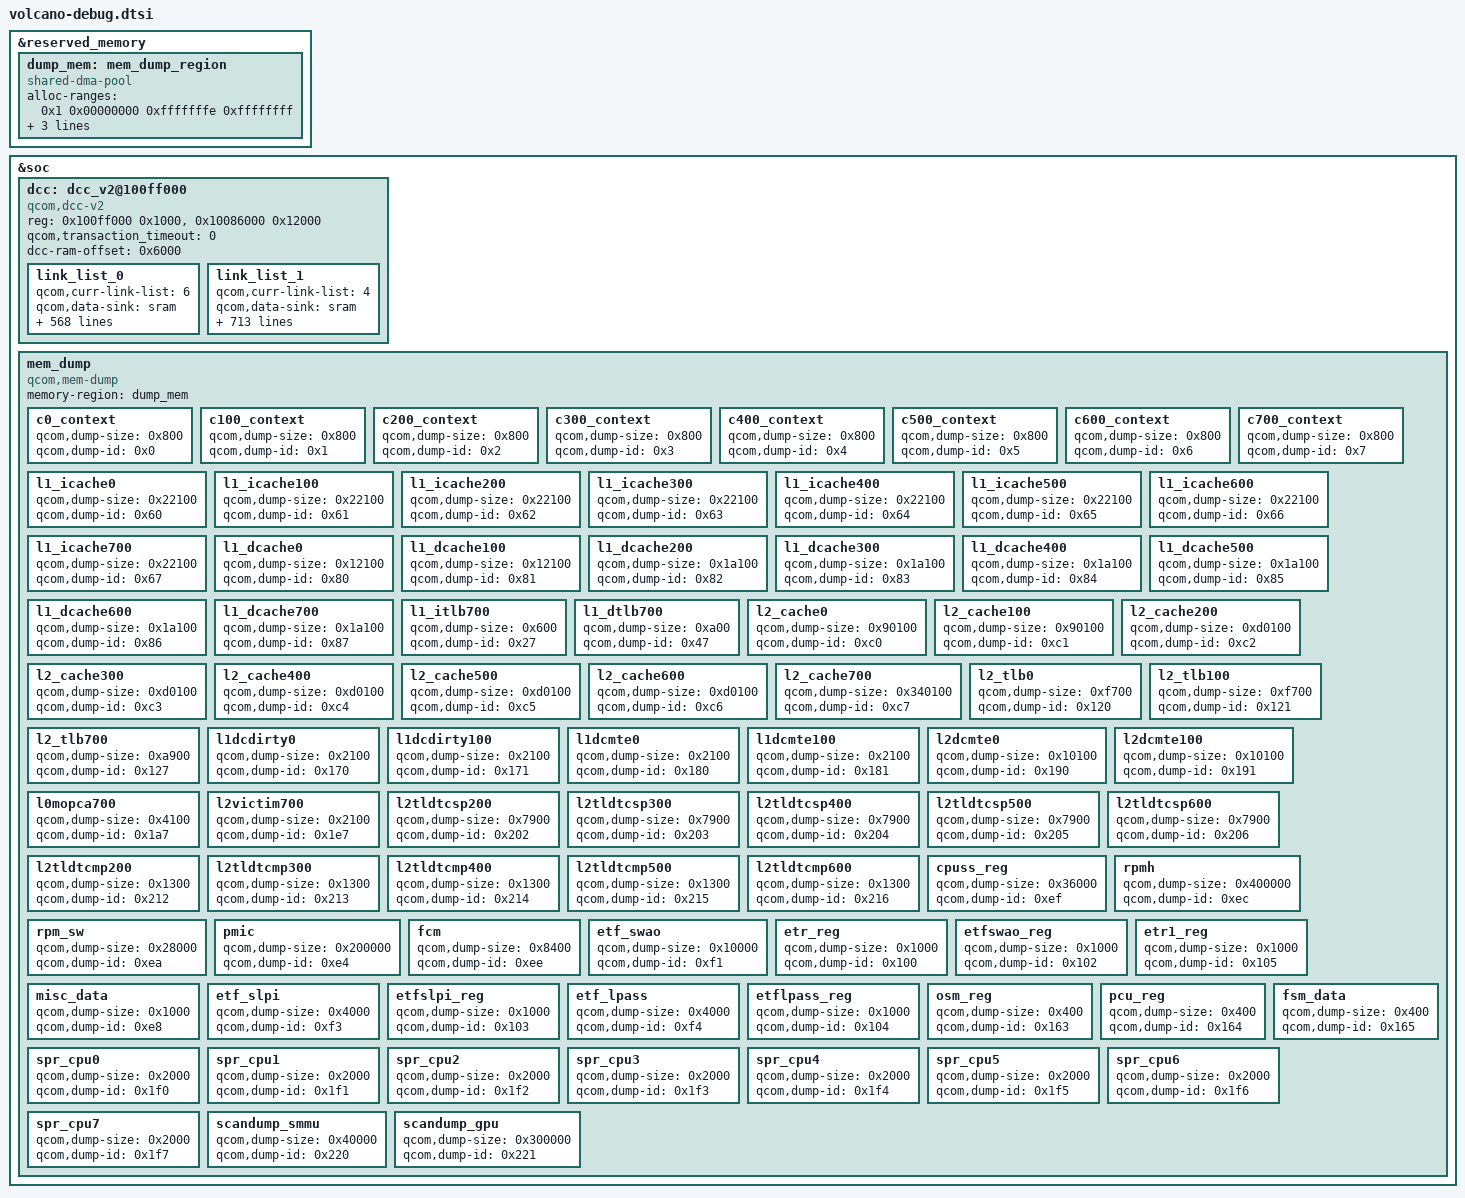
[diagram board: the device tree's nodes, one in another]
#include <dt-bindings/soc/qcom,dcc_v2.h>

&reserved_memory {
	#address-cells = <2>;
	#size-cells = <2>;
	ranges;

	dump_mem: mem_dump_region {
		compatible = "shared-dma-pool";
		alloc-ranges = <0x1 0x00000000 0xfffffffe 0xffffffff>;
		reusable;
		alignment = <0x0 0x400000>;
		size = <0 0x1800000>;
	};
};

&soc {
	dcc: dcc_v2@100ff000 {
		compatible = "qcom,dcc-v2";
		reg = <0x100ff000 0x1000>,
		      <0x10086000 0x12000>;

		qcom,transaction_timeout = <0>;

		reg-names = "dcc-base", "dcc-ram-base";
		dcc-ram-offset = <0x6000>;

		link_list_0 {
			qcom,curr-link-list = <6>;
			qcom,data-sink = "sram";
			qcom,ap-qad-override;
			qcom,link-list = <DCC_READ 0x17421000 2 0>,
				<DCC_READ 0x1780005c 1 0>,
				<DCC_READ 0x1781005c 1 0>,
				<DCC_READ 0x1782005c 1 0>,
				<DCC_READ 0x1783005c 1 0>,
				<DCC_READ 0x1784005c 1 0>,
				<DCC_READ 0x1785005c 1 0>,
				<DCC_READ 0x1786005c 1 0>,
				<DCC_READ 0x1787005c 1 0>,
				<DCC_READ 0x1740003c 1 0>,
				<DCC_READ 0x17600238 1 0>,
				<DCC_READ 0x17600240 11 0>,
				<DCC_READ 0x17600274 1 0>,
				<DCC_READ 0x17600530 1 0>,
				<DCC_READ 0x1760051c 1 0>,
				<DCC_READ 0x17600524 1 0>,
				<DCC_READ 0x1760052c 1 0>,
				<DCC_READ 0x17600518 1 0>,
				<DCC_READ 0x17600520 1 0>,
				<DCC_READ 0x17600528 1 0>,
				<DCC_READ 0x17600404 4 0>,
				<DCC_READ 0x1760041c 4 0>,
				<DCC_READ 0x17600434 1 0>,
				<DCC_READ 0x1760043c 1 0>,
				<DCC_READ 0x17600440 1 0>,
				<DCC_READ 0x17400438 1 0>,
				<DCC_READ 0x17600044 1 0>,
				<DCC_READ 0x17600500 1 0>,
				<DCC_READ 0x221c209c 1 0>,
				<DCC_READ 0x17600504 4 0>,
				<DCC_READ 0x17900908 1 0>,
				<DCC_READ 0x17900c18 1 0>,
				<DCC_READ 0x17901908 1 0>,
				<DCC_READ 0x17901c18 1 0>,
				<DCC_READ 0x17b90810 3 0>,
				<DCC_READ 0x17b90c50 3 0>,
				<DCC_READ 0x17b93a04 2 0>,
				<DCC_READ 0x17b93c94 1 0>,
				<DCC_READ 0x17ba0810 3 0>,
				<DCC_READ 0x17ba0c50 3 0>,
				<DCC_READ 0x17ba3a04 2 0>,
				<DCC_READ 0x17ba3c94 1 0>,
				<DCC_READ 0x17b93000 80 0>,
				<DCC_READ 0x17ba3000 80 0>,
				<DCC_READ 0x0c201244 1 0>,
				<DCC_READ 0x0c202244 1 0>,
				<DCC_READ 0x17b00000 1 0>,
				<DCC_READ 0x17a94030 1 0>,
				<DCC_READ 0x17a9408c 1 0>,
				<DCC_WRITE 0x17a9409c 0x78 0>,
				<DCC_WRITE 0x17a9409c 0x0  0>,
				<DCC_WRITE 0x17a94048 0x1  0>,
				<DCC_WRITE 0x17a94090 0x0  0>,
				<DCC_WRITE 0x17a94090 0x25 0>,
				<DCC_READ 0x17a94098 1 0>,
				<DCC_WRITE 0x17a94048 0x1d 0>,
				<DCC_WRITE 0x17a94090 0x0  0>,
				<DCC_WRITE 0x17a94090 0x25 0>,
				<DCC_READ 0x17a94098 1 0>,
				<DCC_READ 0x17a90030 1 0>,
				<DCC_READ 0x17a9008c 1 0>,
				<DCC_WRITE 0x17a9009c 0x78 0>,
				<DCC_WRITE 0x17a9009c 0x0  0>,
				<DCC_WRITE 0x17a90048 0x1  0>,
				<DCC_WRITE 0x17a90090 0x0  0>,
				<DCC_WRITE 0x17a90090 0x25 0>,
				<DCC_READ 0x17a90098 1 0>,
				<DCC_WRITE 0x17a90048 0x1d 0>,
				<DCC_WRITE 0x17a90090 0x0  0>,
				<DCC_WRITE 0x17a90090 0x25 0>,
				<DCC_READ 0x17a90098 1 0>,
				<DCC_READ 0x17a92030 1 0>,
				<DCC_READ 0x17a9208c 1 0>,
				<DCC_WRITE 0x17a9209c 0x78 0>,
				<DCC_WRITE 0x17a9209c 0x0  0>,
				<DCC_WRITE 0x17a92048 0x1  0>,
				<DCC_WRITE 0x17a92090 0x0  0>,
				<DCC_WRITE 0x17a92090 0x25 0>,
				<DCC_READ 0x17a92098 1 0>,
				<DCC_WRITE 0x17a92048 0x1d 0>,
				<DCC_WRITE 0x17a92090 0x0  0>,
				<DCC_WRITE 0x17a92090 0x25 0>,
				<DCC_READ 0x17a92098 1 0>,
				<DCC_READ 0x17a96030 1 0>,
				<DCC_READ 0x17a9608c 1 0>,
				<DCC_WRITE 0x17a9609c 0x78 0>,
				<DCC_WRITE 0x17a9609c 0x0  0>,
				<DCC_WRITE 0x17a96048 0x1  0>,
				<DCC_WRITE 0x17a96090 0x0  0>,
				<DCC_WRITE 0x17a96090 0x25 0>,
				<DCC_READ 0x17a96098 1 0>,
				<DCC_WRITE 0x17a96048 0x1d 0>,
				<DCC_WRITE 0x17a96090 0x0  0>,
				<DCC_WRITE 0x17a96090 0x25 0>,
				<DCC_READ 0x17a96098 1 0>,
				<DCC_READ 0x17d98024 1 0>,
				<DCC_READ 0x13822000 1 1>,
				<DCC_READ 0x221c20a4 1 0>,
				<DCC_READ 0x01fc8000 1 0>,
				<DCC_READ 0x17400038 1 0>,
				<DCC_READ 0x17d91020 1 0>,
				<DCC_READ 0x17d92020 1 0>,
				<DCC_READ 0x17d93020 1 0>,
				<DCC_READ 0x17d90020 1 0>,
				<DCC_READ 0x17d9134c 1 0>,
				<DCC_READ 0x17d9234c 1 0>,
				<DCC_READ 0x17d9334c 1 0>,
				<DCC_READ 0x17d9034c 1 0>,
				<DCC_READ 0x17d91300 1 0>,
				<DCC_READ 0x17d92300 1 0>,
				<DCC_READ 0x17d93300 1 0>,
				<DCC_READ 0x17d90300 1 0>,
				<DCC_READ 0x24104010 1 >,
				<DCC_READ 0x24104020 6 0>,
				<DCC_READ 0x24144010 1 0>,
				<DCC_READ 0x24144020 6 0>,
				<DCC_READ 0x24190010 1 0>,
				<DCC_READ 0x24190020 6 0>,
				<DCC_READ 0x24190410 1 0>,
				<DCC_READ 0x24190420 6 0>,
				<DCC_READ 0x24191048 1 0>,
				<DCC_READ 0x24100808 2 0>,
				<DCC_READ 0x24140808 2 0>,
				<DCC_READ 0x24101000 3 0>,
				<DCC_LOOP 0x3 0 0>,
				<DCC_READ 0x24101010 2 0>,
				<DCC_LOOP 0x1 0 0>,
				<DCC_READ 0x24101018 1 0>,
				<DCC_READ 0x24101080 1 0>,
				<DCC_READ 0x24101084 2 0>,
				<DCC_LOOP 0x5 0 0>,
				<DCC_READ 0x24101090 2 0>,
				<DCC_LOOP 0x1 0 0>,
				<DCC_READ 0x24101098 1 0>,
				<DCC_READ 0x24141000 1 0>,
				<DCC_READ 0x24141004 2 0>,
				<DCC_READ 0x24141010 2 0>,
				<DCC_READ 0x24141010 2 0>,
				<DCC_READ 0x24141018 1 0>,
				<DCC_READ 0x24141080 1 0>,
				<DCC_READ 0x24141084 1 0>,
				<DCC_LOOP 0x5 0 0>,
				<DCC_READ 0x24141090 2 0>,
				<DCC_LOOP 0x1 0 0>,
				<DCC_READ 0x24141098 1 0>,
				<DCC_READ 0x24181000 1 0>,
				<DCC_READ 0x24181004 2 0>,
				<DCC_LOOP 0x3 0 0>,
				<DCC_READ 0x24181010 2 0>,
				<DCC_LOOP 0x1 0 0>,
				<DCC_READ 0x24181018 1 0>,
				<DCC_READ 0x24181100 3 0>,
				<DCC_LOOP 0xc 0 0>,
				<DCC_READ 0x24181110 2 0>,
				<DCC_LOOP 0x1 0 0>,
				<DCC_READ 0x24181118 1 0>,
				<DCC_READ 0x24131010 1 >,
				<DCC_READ 0x24133010 1 >,
				<DCC_READ 0x24135010 1 >,
				<DCC_READ 0x24137010 1 >,
				<DCC_READ 0x24138010 1 >,
				<DCC_READ 0x24171010 1 >,
				<DCC_READ 0x24173010 1 >,
				<DCC_READ 0x24175010 1 >,
				<DCC_READ 0x24177010 1 >,
				<DCC_READ 0x24178010 1 >,
				<DCC_READ 0x241e2010 1 >,
				<DCC_READ 0x241e5010 1 >,
				<DCC_READ 0x241f1010 1 >,
				<DCC_READ 0x241f3010 1 >,
				<DCC_READ 0x241f5010 1 >,
				<DCC_READ 0x241f7010 1 >,
				<DCC_READ 0x241f9010 1 >,
				<DCC_READ 0x241fb010 1 >,
				<DCC_READ 0x241fc010 1 >,
				<DCC_READ 0x241fd010 1 >,
				<DCC_READ 0x241ff010 1 >,
				<DCC_READ 0x24100810 1 0>,
				<DCC_LOOP 0x40 0 0>,
				<DCC_READ 0x24100830 2 0>,
				<DCC_READ 0x24100830 2 0>,
				<DCC_READ 0x24100830 2 0>,
				<DCC_READ 0x24100830 2 0>,
				<DCC_LOOP 0x1 0 0>,
				<DCC_READ 0x24100838 1 0>,
				<DCC_READ 0x24140810 1 0>,
				<DCC_LOOP 0x40 0 0>,
				<DCC_READ 0x24140830 2 0>,
				<DCC_READ 0x24140830 2 0>,
				<DCC_READ 0x24140830 2 0>,
				<DCC_READ 0x24140830 2 0>,
				<DCC_LOOP 0x1 0 0>,
				<DCC_READ 0x24140838 1 0>,
				<DCC_READ 0x24180010 1 0>,
				<DCC_LOOP 0x10 0 0>,
				<DCC_READ 0x24180030 2 0>,
				<DCC_READ 0x24180030 2 0>,
				<DCC_READ 0x24180030 2 0>,
				<DCC_READ 0x24180030 2 0>,
				<DCC_LOOP 0x1 0 0>,
				<DCC_READ 0x24180038 1 0>,
				<DCC_READ 0x24180410 1 0>,
				<DCC_LOOP 0x10 0 0>,
				<DCC_READ 0x24180430 2 0>,
				<DCC_READ 0x24180430 2 0>,
				<DCC_READ 0x24180430 2 0>,
				<DCC_READ 0x24180430 2 0>,
				<DCC_LOOP 0x1 0 0>,
				<DCC_READ 0x24180438 1 0>,
				<DCC_READ 0x17800024  1 >,
				<DCC_READ 0x17800038  6>,
				<DCC_READ 0x17800058  4>,
				<DCC_READ 0x1780006c  1 >,
				<DCC_READ 0x178000f0  2>,
				<DCC_READ 0x17810024  1 >,
				<DCC_READ 0x17810038  6>,
				<DCC_READ 0x17810058  4>,
				<DCC_READ 0x1781006c  1 >,
				<DCC_READ 0x178100f0  2>,
				<DCC_READ 0x17820010  1 >,
				<DCC_READ 0x17820024  1 >,
				<DCC_READ 0x17820038  6>,
				<DCC_READ 0x17820058  4>,
				<DCC_READ 0x178200f0  2>,
				<DCC_READ 0x17830010  1 >,
				<DCC_READ 0x17830024  1 >,
				<DCC_READ 0x17830038  6>,
				<DCC_READ 0x17830058  4>,
				<DCC_READ 0x178300f0  2>,
				<DCC_READ 0x17840010  1 >,
				<DCC_READ 0x17840024  1 >,
				<DCC_READ 0x17840038  6>,
				<DCC_READ 0x17840058  4>,
				<DCC_READ 0x178400f0  2>,
				<DCC_READ 0x17850010  1 >,
				<DCC_READ 0x17850024  1 >,
				<DCC_READ 0x17850038  6>,
				<DCC_READ 0x17850058  4>,
				<DCC_READ 0x178500f0  2>,
				<DCC_READ 0x17860010  1 >,
				<DCC_READ 0x17860024  1 >,
				<DCC_READ 0x17860038  6>,
				<DCC_READ 0x17860058  4>,
				<DCC_READ 0x178600f0  2>,
				<DCC_READ 0x17870010  1 >,
				<DCC_READ 0x17870024  1 >,
				<DCC_READ 0x17870038  6>,
				<DCC_READ 0x17870058  4>,
				<DCC_READ 0x178700f0  2>,
				<DCC_READ 0x17880010  1 >,
				<DCC_READ 0x17880024  1 >,
				<DCC_READ 0x17880038  6>,
				<DCC_READ 0x17890010  1 >,
				<DCC_READ 0x17890024  1 >,
				<DCC_READ 0x17890038  6>,
				<DCC_READ 0x178b0010  1 >,
				<DCC_READ 0x178b0024  1 >,
				<DCC_READ 0x178b0038  6>,
				<DCC_READ 0x178b006c  5>,
				<DCC_READ 0x178b0084  1 >,
				<DCC_READ 0x178b00f4  5>,
				<DCC_READ 0x178b0118  9>,
				<DCC_READ 0x178b0158  5>,
				<DCC_READ 0x178b0170  2>,
				<DCC_READ 0x178b0188  5>,
				<DCC_READ 0x178b01ac  6>,
				<DCC_READ 0x178b01c8 1 >,
				<DCC_READ 0x178b0204 1 >,
				<DCC_READ 0x178b0244 1 >,
				<DCC_READ 0x17e30000 1 >,
				<DCC_READ 0x17e30008 1 >,
				<DCC_READ 0x17e30010 1 >,
				<DCC_READ 0x17e80000 1 >,
				<DCC_READ 0x17e80008 1 >,
				<DCC_READ 0x17e80010 1 >,
				<DCC_READ 0x17f80000 1 >,
				<DCC_READ 0x17f80008 1 >,
				<DCC_READ 0x17f80010 1 >,
				<DCC_READ 0x18080000 1 >,
				<DCC_READ 0x18080008 1 >,
				<DCC_READ 0x18080010 1 >,
				<DCC_READ 0x18180000 1 >,
				<DCC_READ 0x18180008 1 >,
				<DCC_READ 0x18180010 1 >,
				<DCC_READ 0x18280000 1 >,
				<DCC_READ 0x18280008 1 >,
				<DCC_READ 0x18280010 1 >,
				<DCC_READ 0x18380000 1 >,
				<DCC_READ 0x18380008 1 >,
				<DCC_READ 0x18380010 1 >,
				<DCC_READ 0x18480000 1 >,
				<DCC_READ 0x18480008 1 >,
				<DCC_READ 0x18480010 1 >,
				<DCC_READ 0x18580000 1 >,
				<DCC_READ 0x18580008 1 >,
				<DCC_READ 0x18580010 1 >,
				<DCC_READ 0x24453400 2 >,
				<DCC_READ 0x24042010 1 >,
				<DCC_READ 0x24042040 1 >,
				<DCC_READ 0x2404205c 1 >,
				<DCC_READ 0x24055008 1 >,
				<DCC_READ 0x24055070 1 >,
				<DCC_READ 0x24055948 1 >,
				<DCC_READ 0x24057008 1 >,
				<DCC_READ 0x24057018 1 >,
				<DCC_READ 0x24057028 1 >,
				<DCC_READ 0x24057038 1 >,
				<DCC_READ 0x24080024 1 >,
				<DCC_READ 0x2408002c 1 >,
				<DCC_READ 0x24080034 1 >,
				<DCC_READ 0x2408003c 1 >,
				<DCC_READ 0x24080044 1 >,
				<DCC_READ 0x2408004c 1 >,
				<DCC_READ 0x24080058 1 >,
				<DCC_READ 0x240800c8 1 >,
				<DCC_READ 0x24080144 1 >,
				<DCC_READ 0x2408014c 1 >,
				<DCC_READ 0x24080174 1 >,
				<DCC_READ 0x2408017c 1 >,
				<DCC_READ 0x24080184 1 >,
				<DCC_READ 0x2408018c 1 >,
				<DCC_READ 0x24080194 1 >,
				<DCC_READ 0x2408019c 1 >,
				<DCC_READ 0x240801a4 1 >,
				<DCC_READ 0x240801ac 1 >,
				<DCC_READ 0x24091000 1 >,
				<DCC_READ 0x24092000 1 >,
				<DCC_READ 0x24093000 1 >,
				<DCC_READ 0x24093104 1 >,
				<DCC_READ 0x24094000 1 >,
				<DCC_READ 0x24094000 1 >,
				<DCC_READ 0x24094104 1 >,
				<DCC_READ 0x24094104 1 >,
				<DCC_READ 0x24095220 9 0>,
				<DCC_READ 0x240a1008 1 >,
				<DCC_READ 0x240a80e4 1 >,
				<DCC_READ 0x240a80f8 1 >,
				<DCC_READ 0x240a8100 1 >,
				<DCC_READ 0x240a8110 1 >,
				<DCC_READ 0x240a8120 1 >,
				<DCC_READ 0x240a81c8 1 >,
				<DCC_READ 0x240a8234 1 >,
				<DCC_READ 0x240a82d4 1 >,
				<DCC_READ 0x240a8834 1 >,
				<DCC_READ 0x240a8840 1 >,
				<DCC_READ 0x240a8854 1 >,
				<DCC_READ 0x240a8860 1 >,
				<DCC_READ 0x240a8878 1 >,
				<DCC_READ 0x240a888c 1 >,
				<DCC_READ 0x240a9140 1 >,
				<DCC_READ 0x240a9140 1 >,
				<DCC_READ 0x240a9188 1 >,
				<DCC_READ 0x240a91b8 1 >,
				<DCC_READ 0x240aa034 1 >,
				<DCC_READ 0x240aa04c 1 >,
				<DCC_READ 0x240aa058 1 >,
				<DCC_READ 0x240aa064 1 >,
				<DCC_READ 0x240aa0d4 1 >,
				<DCC_READ 0x24401814 1 >,
				<DCC_READ 0x24403814 1 >,
				<DCC_READ 0x24405014 1 >,
				<DCC_READ 0x24405530 1 >,
				<DCC_READ 0x24406c04 1 >,
				<DCC_READ 0x24406d04 1 >,
				<DCC_READ 0x2440729c 1 >,
				<DCC_READ 0x244072a8 1 >,
				<DCC_READ 0x2440759c 1 >,
				<DCC_READ 0x244075a8 1 >,
				<DCC_READ 0x24443400 1 >,
				<DCC_READ 0x24443420 1 >,
				<DCC_READ 0x24443430 1 >,
				<DCC_READ 0x24443430 1 >,
				<DCC_READ 0x24443460 2 0>,
				<DCC_READ 0x2444390c 1 >,
				<DCC_READ 0x24450304 1 >,
				<DCC_READ 0x24450400 1 >,
				<DCC_READ 0x24450410 1 >,
				<DCC_READ 0x24450430 1 >,
				<DCC_READ 0x24450438 1 >,
				<DCC_READ 0x24450440 1 >,
				<DCC_READ 0x24450448 1 >,
				<DCC_READ 0x244504a0 1 >,
				<DCC_READ 0x244504b0 1 >,
				<DCC_READ 0x244504d0 1 >,
				<DCC_READ 0x244504e0 1 >,
				<DCC_READ 0x24452400 1 >,
				<DCC_READ 0x24452410 1 >,
				<DCC_READ 0x24452418 1 >,
				<DCC_READ 0x24452420 1 >,
				<DCC_READ 0x24452450 1 >,
				<DCC_READ 0x24455110 1 >,
				<DCC_READ 0x24455130 1 >,
				<DCC_READ 0x24455150 1 >,
				<DCC_READ 0x24455170 1 >,
				<DCC_READ 0x24455190 1 >,
				<DCC_READ 0x24455210 1 >,
				<DCC_READ 0x24455230 1 >,
				<DCC_READ 0x244553b0 1 >,
				<DCC_READ 0x24455c00 1 >,
				<DCC_READ 0x24455c28 1 >,
				<DCC_READ 0x24455c4c 1 >,
				<DCC_READ 0x24455c70 1 >,
				<DCC_READ 0x24455c90 2 0>,
				<DCC_READ 0x24456428 3 0>,
				<DCC_READ 0x24459100  1 >,
				<DCC_READ 0x24459110  1 >,
				<DCC_READ 0x24459120 1 >,
				<DCC_READ 0x24480610 1 >,
				<DCC_READ 0x24480624 1 >,
				<DCC_READ 0x24480640 1 >,
				<DCC_READ 0x24480650 1 >,
				<DCC_READ 0x24480670 1 >,
				<DCC_READ 0x24480680 1 >,
				<DCC_READ 0x24501814 1 >,
				<DCC_READ 0x24503814 1 >,
				<DCC_READ 0x24505014 1 >,
				<DCC_READ 0x24505758 1 >,
				<DCC_READ 0x24506c04 1 >,
				<DCC_READ 0x24506d04 1 >,
				<DCC_READ 0x2450729c 1 >,
				<DCC_READ 0x245072a8 1 >,
				<DCC_READ 0x2450759c 1 >,
				<DCC_READ 0x245075a8 1 >,
				<DCC_READ 0x24543400 1 >,
				<DCC_READ 0x24543420 1 >,
				<DCC_READ 0x24543430 1 >,
				<DCC_READ 0x24543430 1 >,
				<DCC_READ 0x24543460 2 0>,
				<DCC_READ 0x2454390c 1 >,
				<DCC_READ 0x24550304 1 >,
				<DCC_READ 0x24550400 1 >,
				<DCC_READ 0x24550410 1 >,
				<DCC_READ 0x24550430 1 >,
				<DCC_READ 0x24550438 1 >,
				<DCC_READ 0x24550440 1 >,
				<DCC_READ 0x24550448 1 >,
				<DCC_READ 0x245504a0 1 >,
				<DCC_READ 0x245504b0 1 >,
				<DCC_READ 0x245504d0 1 >,
				<DCC_READ 0x245504e0 1 >,
				<DCC_READ 0x24552400 1 >,
				<DCC_READ 0x24552410 1 >,
				<DCC_READ 0x24552418 1 >,
				<DCC_READ 0x24552420 1 >,
				<DCC_READ 0x24552450 1 >,
				<DCC_READ 0x24555110 1 >,
				<DCC_READ 0x24555130 1 >,
				<DCC_READ 0x24555150 1 >,
				<DCC_READ 0x24555170 1 >,
				<DCC_READ 0x24555190 1 >,
				<DCC_READ 0x24555210 1 >,
				<DCC_READ 0x24555230 1 >,
				<DCC_READ 0x245553b0 1 >,
				<DCC_READ 0x24555c00 1 >,
				<DCC_READ 0x24555c28 1 >,
				<DCC_READ 0x24555c4c 1 >,
				<DCC_READ 0x24555c70 1 >,
				<DCC_READ 0x24555c90 2 0>,
				<DCC_READ 0x24556428 3 0>,
				<DCC_READ 0x24559100 1 >,
				<DCC_READ 0x24559110 1 >,
				<DCC_READ 0x24559120 1 >,
				<DCC_READ 0x24580640 1 >,
				<DCC_READ 0x24580650 1 >,
				<DCC_READ 0x24580670 1 >,
				<DCC_READ 0x24580680 1 >,
				<DCC_READ 0x0129000  1 >,
				<DCC_READ 0x012903c  1 >,
				<DCC_READ 0x0171004  1 >,
				<DCC_READ 0x017100c  6>,
				<DCC_READ 0x017115c  1 >,
				<DCC_READ 0x017b000  1 >,
				<DCC_READ 0x017b03c  1 >,
				<DCC_READ 0x017c000  1 >,
				<DCC_READ 0x017c03c  1 >,
				<DCC_READ 0x017d000  1 >,
				<DCC_READ 0x017d03c  1 >,
				<DCC_READ 0x017e000  1 >,
				<DCC_READ 0x017e03c  1 >,
				<DCC_READ 0x3d00000  1 >,
				<DCC_READ 0x3d00008  1 >,
				<DCC_READ 0x3d00020  6 >,
				<DCC_READ 0x3d00040  4 >,
				<DCC_READ 0x3d00054  2 >,
				<DCC_READ 0x3d00060  1 >,
				<DCC_READ 0x3d00068  1 >,
				<DCC_READ 0x3d00070  1 >,
				<DCC_READ 0x3d000a0  4 >,
				<DCC_READ 0x3d000b4  13>,
				<DCC_READ 0x3d00100  20>,
				<DCC_READ 0x3d00188  5 >,
				<DCC_READ 0x3d001a4  6 >,
				<DCC_READ 0x3d001c4  2 >,
				<DCC_READ 0x3d001d0  1 >,
				<DCC_READ 0x3d001d8  2>,
				<DCC_READ 0x3d001fc  28>,
				<DCC_READ 0x3d00274  19>,
				<DCC_READ 0x3d002c8  35>,
				<DCC_READ 0x3d0035c  12>,
				<DCC_READ 0x3d00394  2>,
				<DCC_READ 0x3d003a4  9>,
				<DCC_READ 0x3d003d0  3>,
				<DCC_READ 0x3d003e4  16>,
				<DCC_READ 0x3d0042c  4>,
				<DCC_READ 0x3d00444  1 >,
				<DCC_READ 0x3d00450  9>,
				<DCC_READ 0x3d0047c  3>,
				<DCC_READ 0x3d00494  1 >,
				<DCC_READ 0x3d0049c  1 >,
				<DCC_READ 0x3d004a4  1 >,
				<DCC_READ 0x3d004ac  7>,
				<DCC_READ 0x3d004d0  5>,
				<DCC_READ 0x3d004e8  1 >,
				<DCC_READ 0x3d004f0  4>,
				<DCC_READ 0x3d00508  15>,
				<DCC_READ 0x3d0054c  3>,
				<DCC_READ 0x3d00560  2>,
				<DCC_READ 0x3d00570  1 >,
				<DCC_READ 0x3d00598  20>,
				<DCC_READ 0x3d00680  1 >,
				<DCC_READ 0x3d00f80  1 >,
				<DCC_READ 0x3d00fc0  1 >,
				<DCC_READ 0x3d01100  1 >,
				<DCC_READ 0x3d02000  11>,
				<DCC_READ 0x3d0204c  12>,
				<DCC_READ 0x3d02080  4>,
				<DCC_READ 0x3d020d8  9>,
				<DCC_READ 0x3d02100  8>,
				<DCC_READ 0x3d0212c  5>,
				<DCC_READ 0x3d022c0  12>,
				<DCC_READ 0x3d02300  12>,
				<DCC_READ 0x3d0239c  5>,
				<DCC_READ 0x3d0f000  12>,
				<DCC_READ 0x3d0f100  3>,
				<DCC_READ 0x3d0f114  3>,
				<DCC_READ 0x3d0f124  6>,
				<DCC_READ 0x3d3c000  3>,
				<DCC_READ 0x3d3d000  1 >,
				<DCC_READ 0x3d3e000  4>,
				<DCC_READ 0x3d3f000  2>,
				<DCC_READ 0x3d50000  21>,
				<DCC_READ 0x3d500d0  1 >,
				<DCC_READ 0x3d500d8  1 >,
				<DCC_READ 0x3d50100  3>,
				<DCC_READ 0x3d50110  2>,
				<DCC_READ 0x3d5011c  1 >,
				<DCC_READ 0x3d50200  5>,
				<DCC_READ 0x3d50400  5>,
				<DCC_READ 0x3d50450  1 >,
				<DCC_READ 0x3d50460  2>,
				<DCC_READ 0x3d50490  12>,
				<DCC_READ 0x3d50550  1 >,
				<DCC_READ 0x3d50d00  2>,
				<DCC_READ 0x3d50d10  1 >,
				<DCC_READ 0x3d50d18  13>,
				<DCC_READ 0x3d50fe0  1 >,
				<DCC_READ 0x3d50ff8  1 >,
				<DCC_READ 0x3d51010  1 >,
				<DCC_READ 0x3d51028  1 >,
				<DCC_READ 0x3d51280  1 >,
				<DCC_READ 0x3d51520  1 >,
				<DCC_READ 0x3d51538  1 >,
				<DCC_READ 0x3d51550  1 >,
				<DCC_READ 0x3d517c0  1 >,
				<DCC_READ 0x3d51a60  1 >,
				<DCC_READ 0x3d51a78  1 >,
				<DCC_READ 0x3d51a90  1 >,
				<DCC_READ 0x3d51aa8  1 >,
				<DCC_READ 0x3d51d00  1 >,
				<DCC_READ 0x3d51fa0  1 >,
				<DCC_READ 0x3d51fb8  1 >,
				<DCC_READ 0x3d52240  1 >,
				<DCC_READ 0x3d52258  1 >,
				<DCC_READ 0x3d524e0  1 >,
				<DCC_READ 0x3d64000  13>,
				<DCC_READ 0x3d6403c  1 >,
				<DCC_READ 0x3d66000  6>,
				<DCC_READ 0x3d67000  1 >,
				<DCC_READ 0x3d68000  5>,
				<DCC_READ 0x3d68020  11>,
				<DCC_READ 0x3d68050  1 >,
				<DCC_READ 0x3d6805c  1 >,
				<DCC_READ 0x3d68064  1 >,
				<DCC_READ 0x3d68088  1 >,
				<DCC_READ 0x3d68090  6>,
				<DCC_READ 0x3d680fc  31>,
				<DCC_READ 0x3d68180  4>,
				<DCC_READ 0x3d68194  2>,
				<DCC_READ 0x3d681a0  15>,
				<DCC_READ 0x3d681e0  4>,
				<DCC_READ 0x3d69000  23>,
				<DCC_READ 0x3d69080  14>,
				<DCC_READ 0x3d690c0  2>,
				<DCC_READ 0x3d690d4  1 >,
				<DCC_READ 0x3d690dc  1 >,
				<DCC_READ 0x3d690e8  1 >,
				<DCC_READ 0x3d69108  1 >,
				<DCC_READ 0x3d69158  3>,
				<DCC_READ 0x3d6916c  3>,
				<DCC_READ 0x3d6917c  4>,
				<DCC_READ 0x3d7d000  12>,
				<DCC_READ 0x3d7d03c  3>,
				<DCC_READ 0x3d7d400  1 >,
				<DCC_READ 0x3d7d41c  1 >,
				<DCC_READ 0x3d7d424  3>,
				<DCC_READ 0x3d7dc58  1 >,
				<DCC_READ 0x3d7dc94  1 >,
				<DCC_READ 0x3d7dca4  1 >,
				<DCC_READ 0x3d7dd58  2>,
				<DCC_READ 0x3d7df80  2>,
				<DCC_READ 0x3d7df90  2>,
				<DCC_READ 0x3d7dfa0  2>,
				<DCC_READ 0x3d7dfb0  2>,
				<DCC_READ 0x3d7e000  5>,
				<DCC_READ 0x3d7e01c  2>,
				<DCC_READ 0x3d7e02c  2>,
				<DCC_READ 0x3d7e03c  1 >,
				<DCC_READ 0x3d7e044  1 >,
				<DCC_READ 0x3d7e04c  5>,
				<DCC_READ 0x3d7e064  4>,
				<DCC_READ 0x3d7e090  13>,
				<DCC_READ 0x3d7e100  2>,
				<DCC_READ 0x3d7e130  1 >,
				<DCC_READ 0x3d7e140  1 >,
				<DCC_READ 0x3d7e500  2>,
				<DCC_READ 0x3d7e50c  1 >,
				<DCC_READ 0x3d7e520  1 >,
				<DCC_READ 0x3d7e53c  1 >,
				<DCC_READ 0x3d7e550  2>,
				<DCC_READ 0x3d7e574  1 >,
				<DCC_READ 0x3d7e5c0  1 >,
				<DCC_READ 0x3d7e5f0  3>,
				<DCC_READ 0x3d7e600  2>,
				<DCC_READ 0x3d7e610  3>,
				<DCC_READ 0x3d7e648  2>,
				<DCC_READ 0x3d7e658  9>,
				<DCC_READ 0x3d7e700  16>,
				<DCC_READ 0x3d7e7c4  1 >,
				<DCC_READ 0x3d7e7e0  3>,
				<DCC_READ 0x3d7e7f0  1 >,
				<DCC_READ 0x3d7e800  4>,
				<DCC_READ 0x3d7f050  1 >,
				<DCC_READ 0x3d7f060  2>,
				<DCC_READ 0x3d7f080  1 >,
				<DCC_READ 0x3d7f090  3>,
				<DCC_READ 0x3d80080  1 >,
				<DCC_READ 0x3d800d0  3>,
				<DCC_READ 0x3d80c80  3>,
				<DCC_READ 0x3d80c90  3>,
				<DCC_READ 0x3d80ca0  3>,
				<DCC_READ 0x3d80d40  1 >,
				<DCC_READ 0x3d8e100  8>,
				<DCC_READ 0x3d8ec00  2>,
				<DCC_READ 0x3d8ec0c  1 >,
				<DCC_READ 0x3d8ec14  10>,
				<DCC_READ 0x3d8ec40  4>,
				<DCC_READ 0x3d8ec54  2>,
				<DCC_READ 0x3d8eca0  1 >,
				<DCC_READ 0x3d8ecc0  1 >,
				<DCC_READ 0x3d9200c  3>,
				<DCC_READ 0x3d93000  1 >,
				<DCC_READ 0x3d94000  3>,
				<DCC_READ 0x3d95000  5>,
				<DCC_READ 0x3d96000  5>,
				<DCC_READ 0x3d97000  5>,
				<DCC_READ 0x3d98000  5>,
				<DCC_READ 0x3d99000  7>,
				<DCC_READ 0x3d99054  9>,
				<DCC_READ 0x3d9907c  25>,
				<DCC_READ 0x3d990e4  3>,
				<DCC_READ 0x3d990f4  3>,
				<DCC_READ 0x3d9910c  2>,
				<DCC_READ 0x3d991e0  3>,
				<DCC_READ 0x3d99224  2>,
				<DCC_READ 0x3d99270  3>,
				<DCC_READ 0x3d99280  2>,
				<DCC_READ 0x3d99314  3>,
				<DCC_READ 0x3d993a0  3>,
				<DCC_READ 0x3d993e4  4>,
				<DCC_READ 0x3d9942c  1 >,
				<DCC_READ 0x3d99470  3>,
				<DCC_READ 0x3d99500  12>,
				<DCC_READ 0x3d99550  3>,
				<DCC_READ 0x3d99560  5>,
				<DCC_READ 0x3d99578  2>,
				<DCC_READ 0x3d9958c  1 >,
				<DCC_READ 0x3d995b4  7>,
				<DCC_READ 0x3d995d8  1 >,
				<DCC_READ 0x3d995e0  3>,
				<DCC_READ 0x3d9e000  1 >,
				<DCC_READ 0x3d9e040  5>,
				<DCC_READ 0x3d9e080  5>,
				<DCC_READ 0x3d9e0a0  3>,
				<DCC_READ 0x3d9e0c8  11>,
				<DCC_READ 0x3d9e0f8  26>,
				<DCC_READ 0x3d9e200  4>,
				<DCC_READ 0x3d9f000  2>,
				<DCC_READ 0x17421000 2 0>;
		};

		link_list_1 {
			qcom,curr-link-list = <4>;
			qcom,data-sink = "sram";
			qcom,ap-qad-override;
			qcom,link-list = <DCC_READ 0x17421000 2 0>,
				<DCC_READ 0x01400008 1 >,
				<DCC_READ 0x01400010 1 >,
				<DCC_READ 0x01400018 1 >,
				<DCC_READ 0x01400020 8 0>,
				<DCC_READ 0x01418010 1 0>,
				<DCC_READ 0x0145be40 1 0>,
				<DCC_READ 0x0145be48 1 0>,
				<DCC_READ 0x142a010 1 >,
				<DCC_READ 0x142b010 1 >,
				<DCC_READ 0x142c010 1 >,
				<DCC_READ 0x1430010 1 >,
				<DCC_READ 0x0145b808 1 0>,
				<DCC_READ 0x0145b818 1 0>,
				<DCC_LOOP 0x6  0 0>,
				<DCC_READ 0x0145b810 2 0>,
				<DCC_LOOP 0x1 0 0>,
				<DCC_READ 0x1403008 1 0>,
				<DCC_READ 0x1403018 1 0>,
				<DCC_LOOP 0x7  0 0>,
				<DCC_READ 0x1403010 2 0>,
				<DCC_LOOP 0x1 0 0>,
				<DCC_READ 0x01480008 1 0>,
				<DCC_READ 0x01480010 1 0>,
				<DCC_READ 0x01480018 1 0>,
				<DCC_READ 0x01480020 8 0>,
				<DCC_READ 0x01480248 1 0>,
				<DCC_READ 0x14a8010 1 >,
				<DCC_READ 0x14a9010 1 >,
				<DCC_READ 0x14ad010 1 >,
				<DCC_READ 0x01482008 1 0>,
				<DCC_READ 0x01482018 1 0>,
				<DCC_LOOP 0x7  0 0>,
				<DCC_READ 0x01482010 2 0>,
				<DCC_LOOP 0x1 0 0>,
				<DCC_READ 0x1483008 1 0>,
				<DCC_READ 0x1483018 1 0>,
				<DCC_LOOP 0x9  0 0>,
				<DCC_READ 0x1483010 2 0>,
				<DCC_LOOP 0x1 0 0>,
				<DCC_READ 0x01680008 1 0>,
				<DCC_READ 0x01680010 1 0>,
				<DCC_READ 0x01680018 1 0>,
				<DCC_READ 0x01680020 8 0>,
				<DCC_READ 0x01681040 1 0>,
				<DCC_READ 0x01681048 1 0>,
				<DCC_READ 0x1690010 1 0>,
				<DCC_READ 0x169a010 1 0>,
				<DCC_READ 0x169b010 1 0>,
				<DCC_READ 0x169c010 1 0>,
				<DCC_READ 0x169d010 1 0>,
				<DCC_READ 0x169e010 1 0>,
				<DCC_READ 0x169f010 1 0>,
				<DCC_READ 0x01682018 1 0>,
				<DCC_READ 0x01682008 1 0>,
				<DCC_LOOP 0x7  0 0>,
				<DCC_READ 0x01682010 2 0>,
				<DCC_LOOP 0x1 0 0>,
				<DCC_READ 0x016e0000 3 0>,
				<DCC_READ 0x016e0010 1 >,
				<DCC_READ 0x016e0018 1 >,
				<DCC_READ 0x016e0020 8 0>,
				<DCC_READ 0x016e0240 1 >,
				<DCC_READ 0x016e0248 1 >,
				<DCC_READ 0x16ec010 1 >,
				<DCC_READ 0x16ef210 1 >,
				<DCC_READ 0x16f0010 1 >,
				<DCC_READ 0x016e1088 1 0>,
				<DCC_READ 0x016e1098 1 0>,
				<DCC_LOOP 0x3  0 0>,
				<DCC_READ 0x16e1090 2 0>,
				<DCC_LOOP 0x1 0 0>,
				<DCC_READ 0x016e1118 1 0>,
				<DCC_READ 0x016e1108 1 0>,
				<DCC_LOOP 0x6  0 0>,
				<DCC_READ 0x016e1110 2 0>,
				<DCC_LOOP 0x1 0 0>,
				<DCC_READ 0x01700000 3 0>,
				<DCC_READ 0x01700010 1 0>,
				<DCC_READ 0x01700018 1 0>,
				<DCC_READ 0x01700020 8 0>,
				<DCC_READ 0x01700240 1 0>,
				<DCC_READ 0x01700248 1 0>,
				<DCC_READ 0x1712010 1 >,
				<DCC_READ 0x1713010 1 >,
				<DCC_READ 0x1714010 1 >,
				<DCC_READ 0x1715010 1 >,
				<DCC_READ 0x1716010 1 >,
				<DCC_READ 0x1717010 1 >,
				<DCC_READ 0x1718010 1 >,
				<DCC_READ 0x1719010 1 >,
				<DCC_READ 0x171a010 1 >,
				<DCC_READ 0x01701018 1 0>,
				<DCC_READ 0x01701008 1 0>,
				<DCC_LOOP 0x6  0 0>,
				<DCC_READ 0x01701010 2 0>,
				<DCC_LOOP 0x1 0 0>,
				<DCC_READ 0x01701288 1 0>,
				<DCC_READ 0x01701298 1 0>,
				<DCC_LOOP 0x3  0 0>,
				<DCC_READ 0x01701290 2 0>,
				<DCC_LOOP 0x1  0 0>,
				<DCC_READ 0x16c0000 3 0>,
				<DCC_READ 0x16c0010 1 >,
				<DCC_READ 0x16c0018 1 >,
				<DCC_READ 0x16c0020 8 0>,
				<DCC_READ 0x16c0240 1 >,
				<DCC_READ 0x16c0248 1 >,
				<DCC_READ 0x16cb010 1 >,
				<DCC_READ 0x16cc010 1 >,
				<DCC_READ 0x16c2008 1 >,
				<DCC_READ 0x16c2018 1 >,
				<DCC_LOOP 0x4  0 0>,
				<DCC_READ 0x016c2010 2 0>,
				<DCC_LOOP 0x1 0 0>,
				<DCC_READ 0x16c3008 1 >,
				<DCC_READ 0x16c3018 1 >,
				<DCC_LOOP 0x4  0 0>,
				<DCC_READ 0x016c3010 2 0>,
				<DCC_LOOP 0x1 0 0>,
				<DCC_READ 0x1600008 1 >,
				<DCC_READ 0x1600010 1 >,
				<DCC_READ 0x1600018 1 >,
				<DCC_READ 0x1600020 8 0>,
				<DCC_READ 0x1600240 5 0>,
				<DCC_READ 0x1600258 1 >,
				<DCC_READ 0x01602018 1 0>,
				<DCC_READ 0x01602008 1 0>,
				<DCC_LOOP 0x8  0 0>,
				<DCC_READ 0x01602010 2 0>,
				<DCC_LOOP 0x1 0 0>,
				<DCC_READ 0x01602108 1 0>,
				<DCC_READ 0x01602118 1 0>,
				<DCC_LOOP 0x2  0 0>,
				<DCC_READ 0x01602110 2 0>,
				<DCC_LOOP 0x1 0 0>,
				<DCC_READ 0x01602188 1 0>,
				<DCC_READ 0x01602198 1 0>,
				<DCC_LOOP 0x2 0 0>,
				<DCC_READ 0x01602190 2 0>,
				<DCC_LOOP 0x1 0 0>,
				<DCC_READ 0x01602288 1 0>,
				<DCC_READ 0x01602298 1 0>,
				<DCC_LOOP 0x3  0 0>,
				<DCC_READ 0x01602290 2 0>,
				<DCC_LOOP 0x1 0 0>,
				<DCC_READ 0x01602388 1 0>,
				<DCC_READ 0x01602398 1 0>,
				<DCC_LOOP 0x3  0 0>,
				<DCC_READ 0x01602390 2 0>,
				<DCC_LOOP 0x1 0 0>,
				<DCC_READ 0x1500008 1 >,
				<DCC_READ 0x1500010 1 >,
				<DCC_READ 0x1500018 1 >,
				<DCC_READ 0x1500020 8 0>,
				<DCC_READ 0x1500240 1 >,
				<DCC_READ 0x1500248 1 >,
				<DCC_READ 0x1500440 1 >,
				<DCC_READ 0x1500448 1 >,
				<DCC_READ 0x01502018 1 0>,
				<DCC_READ 0x01502008 1 0>,
				<DCC_LOOP 0xb  0 0>,
				<DCC_READ 0x01502010 2 0>,
				<DCC_LOOP 0x1 0 0>,
				<DCC_READ 0x01502098 1 0>,
				<DCC_READ 0x01502088 1 0>,
				<DCC_LOOP 0x3  0 0>,
				<DCC_READ 0x01502090 2 0>,
				<DCC_LOOP 0x1 0 0>,
				<DCC_READ 0xb281024 1 0>,
				<DCC_READ 0xbde1034 1 0>,
				<DCC_READ 0xb201020 2 0>,
				<DCC_READ 0xb211020 2 0>,
				<DCC_READ 0xb221020 2 0>,
				<DCC_READ 0xb231020 2 0>,
				<DCC_READ 0xb204520 1 0>,
				<DCC_READ 0xb200000 1 0>,
				<DCC_READ 0xb210000 1 0>,
				<DCC_READ 0xb220000 1 0>,
				<DCC_READ 0xb230000 1 0>,
				<DCC_READ 0x17a00010 1 0>,
				<DCC_READ 0x17a10010 1 0>,
				<DCC_READ 0x17a20010 1 0>,
				<DCC_READ 0x17a30010 1 0>,
				<DCC_READ 0x17a00030 1 0>,
				<DCC_READ 0x17a10030 1 0>,
				<DCC_READ 0x17a20030 1 0>,
				<DCC_READ 0x17a30030 1 0>,
				<DCC_READ 0x17a00038 1 0>,
				<DCC_READ 0x17a10038 1 0>,
				<DCC_READ 0x17a20038 1 0>,
				<DCC_READ 0x17a30038 1 0>,
				<DCC_READ 0x17a00040 1 0>,
				<DCC_READ 0x17a10040 1 0>,
				<DCC_READ 0x17a20040 1 0>,
				<DCC_READ 0x17a30040 1 0>,
				<DCC_READ 0x17a00048 1 0>,
				<DCC_READ 0x17a00400 3 0>,
				<DCC_READ 0x17a10400 3 0>,
				<DCC_READ 0x17a20400 3 0>,
				<DCC_READ 0x17a30400 3 0>,
				<DCC_READ 0x17a10d3c 1 0>,
				<DCC_READ 0x17a10d54 1 0>,
				<DCC_READ 0x17a10d6c 1 0>,
				<DCC_READ 0x17a10d84 1 0>,
				<DCC_READ 0x17a10d9c 1 0>,
				<DCC_READ 0x17a10db4 1 0>,
				<DCC_READ 0x17a10dcc 1 0>,
				<DCC_READ 0x17a10de4 1 0>,
				<DCC_READ 0x17a10dfc 1 0>,
				<DCC_READ 0x17a10e14 1 0>,
				<DCC_READ 0x17a10e2c 1 0>,
				<DCC_READ 0x17a10e44 1 0>,
				<DCC_READ 0x17a10e5c 1 0>,
				<DCC_READ 0x17a10e74 1 0>,
				<DCC_READ 0x17a10e8c 1 0>,
				<DCC_READ 0x17a10ea4 1 0>,
				<DCC_READ 0x17a10fdc 1 0>,
				<DCC_READ 0x17a10ff4 1 0>,
				<DCC_READ 0x17a1100c 1 0>,
				<DCC_READ 0x17a11024 1 0>,
				<DCC_READ 0x17a1103c 1 0>,
				<DCC_READ 0x17a11054 1 0>,
				<DCC_READ 0x17a1106c 1 0>,
				<DCC_READ 0x17a11084 1 0>,
				<DCC_READ 0x17a1109c 1 0>,
				<DCC_READ 0x17a110b4 1 0>,
				<DCC_READ 0x17a110cc 1 0>,
				<DCC_READ 0x17a110e4 1 0>,
				<DCC_READ 0x17a110fc 1 0>,
				<DCC_READ 0x17a11114 1 0>,
				<DCC_READ 0x17a1112c 1 0>,
				<DCC_READ 0x17a11144 1 0>,
				<DCC_READ 0x17a1127c 1 0>,
				<DCC_READ 0x17a11294 1 0>,
				<DCC_READ 0x17a112ac 1 0>,
				<DCC_READ 0x17a112c4 1 0>,
				<DCC_READ 0x17a112dc 1 0>,
				<DCC_READ 0x17a112f4 1 0>,
				<DCC_READ 0x17a1130c 1 0>,
				<DCC_READ 0x17a11324 1 0>,
				<DCC_READ 0x17a1133c 1 0>,
				<DCC_READ 0x17a11354 1 0>,
				<DCC_READ 0x17a1136c 1 0>,
				<DCC_READ 0x17a11384 1 0>,
				<DCC_READ 0x17a1139c 1 0>,
				<DCC_READ 0x17a113b4 1 0>,
				<DCC_READ 0x17a113cc 1 0>,
				<DCC_READ 0x17a113e4 1 0>,
				<DCC_READ 0x17a1151c 1 0>,
				<DCC_READ 0x17a11534 1 0>,
				<DCC_READ 0x17a1154c 1 0>,
				<DCC_READ 0x17a11564 1 0>,
				<DCC_READ 0x17a1157c 1 0>,
				<DCC_READ 0x17a11594 1 0>,
				<DCC_READ 0x17a115ac 1 0>,
				<DCC_READ 0x17a115c4 1 0>,
				<DCC_READ 0x17a115dc 1 0>,
				<DCC_READ 0x17a115f4 1 0>,
				<DCC_READ 0x17a1160c 1 0>,
				<DCC_READ 0x17a11624 1 0>,
				<DCC_READ 0x17a1163c 1 0>,
				<DCC_READ 0x17a11654 1 0>,
				<DCC_READ 0x17a1166c 1 0>,
				<DCC_READ 0x17a11684 1 0>,
				<DCC_READ 0xc234004 5 0>,
				<DCC_LOOP 0x5 0 0>,
				<DCC_READ 0x17410000 6 0>,
				<DCC_READ 0x17411000 6 0>,
				<DCC_LOOP 0x1 0 0>,
				<DCC_READ 0x150075dc 1 0>,
				<DCC_READ 0x15002204 1 0>,
				<DCC_READ 0x15002670 1 0>,
				<DCC_READ 0x17d9001c 1 0>,
				<DCC_READ 0x17d900dc 1 0>,
				<DCC_READ 0x17d900e8 1 0>,
				<DCC_READ 0x17d90320 1 0>,
				<DCC_READ 0x17d9101c 1 0>,
				<DCC_READ 0x17d910dc 1 0>,
				<DCC_READ 0x17d910e8 1 0>,
				<DCC_READ 0x17d91320 1 0>,
				<DCC_READ 0x17d9201c 1 0>,
				<DCC_READ 0x17d920dc 1 0>,
				<DCC_READ 0x17d920e8 1 0>,
				<DCC_READ 0x17d92320 1 0>,
				<DCC_READ 0x17d90000 4 0>,
				<DCC_READ 0x17d90014 2 0>,
				<DCC_READ 0x17d90024 22 0>,
				<DCC_READ 0x17d90080 5 0>,
				<DCC_READ 0x17d900b0 1 0>,
				<DCC_READ 0x17d900b8 2 0>,
				<DCC_READ 0x17d900d0 3 0>,
				<DCC_READ 0x17d900e0 2 0>,
				<DCC_READ 0x17d900ec 2 0>,
				<DCC_READ 0x17d90100 40 0>,
				<DCC_READ 0x17d90200 40 0>,
				<DCC_READ 0x17d90304 4 0>,
				<DCC_READ 0x17d90350 30 0>,
				<DCC_READ 0x17d903e0 2 0>,
				<DCC_READ 0x17d90404 1 0>,
				<DCC_READ 0x17d91000 4 0>,
				<DCC_READ 0x17d91014 2 0>,
				<DCC_READ 0x17d91024 22 0>,
				<DCC_READ 0x17d91080 8 0>,
				<DCC_READ 0x17d910b0 1 0>,
				<DCC_READ 0x17d910b8 2 0>,
				<DCC_READ 0x17d910d0 3 0>,
				<DCC_READ 0x17d910e0 2 0>,
				<DCC_READ 0x17d910ec 2 0>,
				<DCC_READ 0x17d91100 40 0>,
				<DCC_READ 0x17d91200 40 0>,
				<DCC_READ 0x17d91304 4 0>,
				<DCC_READ 0x17d91324 3 0>,
				<DCC_READ 0x17d91350 34 0>,
				<DCC_READ 0x17d913e0 5 0>,
				<DCC_READ 0x17d91404 1 0>,
				<DCC_READ 0x17d92000 4 0>,
				<DCC_READ 0x17d92014 2 0>,
				<DCC_READ 0x17d92024 22 0>,
				<DCC_READ 0x17d92080 7 0>,
				<DCC_READ 0x17d920b0 1 0>,
				<DCC_READ 0x17d920b8 2 0>,
				<DCC_READ 0x17d920d0 3 0>,
				<DCC_READ 0x17d920e0 2 0>,
				<DCC_READ 0x17d920ec 2 0>,
				<DCC_READ 0x17d92100 40 0>,
				<DCC_READ 0x17d92200 40 0>,
				<DCC_READ 0x17d92304 4 0>,
				<DCC_READ 0x17d92324 2 0>,
				<DCC_READ 0x17d92350 33 0>,
				<DCC_READ 0x17d923e0 4 0>,
				<DCC_READ 0x17d92404 1 0>,
				<DCC_READ 0x17d98000 8 0>,
				<DCC_READ 0x17d98020 2 0>,
				<DCC_READ 0x30b0208 3 0>,
				<DCC_READ 0x30b0228 3 0>,
				<DCC_READ 0x30b0248 3 0>,
				<DCC_READ 0x30b0268 3 0>,
				<DCC_READ 0x30b0288 3 0>,
				<DCC_READ 0x30b02a8 3 0>,
				<DCC_READ 0x30b0404 2 0>,
				<DCC_READ 0x3480208 3 0>,
				<DCC_READ 0x3480228 3 0>,
				<DCC_READ 0x3480248 3 0>,
				<DCC_READ 0x3480268 3 0>,
				<DCC_READ 0x3480288 3 0>,
				<DCC_READ 0x34802a8 3 0>,
				<DCC_READ 0x320a4208 2 0>,
				<DCC_READ 0x320a4228 3 0>,
				<DCC_READ 0x320a4248 3 0>,
				<DCC_READ 0x320a4268 3 0>,
				<DCC_READ 0x320a4288 3 0>,
				<DCC_READ 0x320a42a8 3 0>,
				<DCC_READ 0x320a4400 3 0>,
				<DCC_READ 0x32302028 1 0>,
				<DCC_READ 0x323b0208 3 0>,
				<DCC_READ 0x323b0228 3 0>,
				<DCC_READ 0x323b0248 3 0>,
				<DCC_READ 0x323b0268 3 0>,
				<DCC_READ 0x323b0288 3 0>,
				<DCC_READ 0x323b02a8 3 0>,
				<DCC_READ 0x323b0400 3 0>,
				<DCC_READ 0x4080304 1 >,
				<DCC_READ 0x4082028 1 >,
				<DCC_READ 0x4130208 3 0>,
				<DCC_READ 0x4130228 3 0>,
				<DCC_READ 0x4130248 3 0>,
				<DCC_READ 0x4130268 3 0>,
				<DCC_READ 0x4130288 3 0>,
				<DCC_READ 0x41302a8 3 0>,
				<DCC_READ 0x4130400 3 0>,
				<DCC_READ 0x4200208 3 0>,
				<DCC_READ 0x4200228 3 0>,
				<DCC_READ 0x4200248 3 0>,
				<DCC_READ 0x4200268 3 0>,
				<DCC_READ 0x4200288 3 0>,
				<DCC_READ 0x42002a8 3 0>,
				<DCC_READ 0x4200400 3 0>,
				<DCC_READ 0x8a00304 1 >,
				<DCC_READ 0x8a02028 1 >,
				<DCC_READ 0x8ac0208 3 0>,
				<DCC_READ 0x8ac0228 3 0>,
				<DCC_READ 0x8ac0248 3 0>,
				<DCC_READ 0x8ac0268 3 0>,
				<DCC_READ 0x8ac0288 3 0>,
				<DCC_READ 0x8ac02ac 2 0>,
				<DCC_READ 0x8ac02a8 1 >,
				<DCC_READ 0x8ac0400 3 0>,
				<DCC_READ 0x17120000 1 >,
				<DCC_READ 0x17120008 1 >,
				<DCC_READ 0x17120010 1 >,
				<DCC_READ 0x17120018 1 >,
				<DCC_READ 0x17120020 1 >,
				<DCC_READ 0x17120028 1 >,
				<DCC_READ 0x17120040 1 >,
				<DCC_READ 0x17120048 1 >,
				<DCC_READ 0x17120050 1 >,
				<DCC_READ 0x17120058 1 >,
				<DCC_READ 0x17120060 1 >,
				<DCC_READ 0x17120068 1 >,
				<DCC_READ 0x17120080 1 >,
				<DCC_READ 0x17120088 1 >,
				<DCC_READ 0x17120090 1 >,
				<DCC_READ 0x17120098 1 >,
				<DCC_READ 0x171200a0 1 >,
				<DCC_READ 0x171200a8 1 >,
				<DCC_READ 0x171200c0 1 >,
				<DCC_READ 0x171200c8 1 >,
				<DCC_READ 0x171200d0 1 >,
				<DCC_READ 0x171200d8 1 >,
				<DCC_READ 0x171200e0 1 >,
				<DCC_READ 0x171200e8 1 >,
				<DCC_READ 0x17120100 1 >,
				<DCC_READ 0x17120108 1 >,
				<DCC_READ 0x17120110 1 >,
				<DCC_READ 0x17120118 1 >,
				<DCC_READ 0x17120120 1 >,
				<DCC_READ 0x17120128 1 >,
				<DCC_READ 0x17120140 1 >,
				<DCC_READ 0x17120148 1 >,
				<DCC_READ 0x17120150 1 >,
				<DCC_READ 0x17120158 1 >,
				<DCC_READ 0x17120160 1 >,
				<DCC_READ 0x17120168 1 >,
				<DCC_READ 0x17120180 1 >,
				<DCC_READ 0x17120188 1 >,
				<DCC_READ 0x17120190 1 >,
				<DCC_READ 0x17120198 1 >,
				<DCC_READ 0x171201a0 1 >,
				<DCC_READ 0x171201a8 1 >,
				<DCC_READ 0x171201c0 1 >,
				<DCC_READ 0x171201c8 1 >,
				<DCC_READ 0x171201d0 1 >,
				<DCC_READ 0x171201d8 1 >,
				<DCC_READ 0x171201e0 1 >,
				<DCC_READ 0x171201e8 1 >,
				<DCC_READ 0x17120200 1 >,
				<DCC_READ 0x17120208 1 >,
				<DCC_READ 0x17120210 1 >,
				<DCC_READ 0x17120218 1 >,
				<DCC_READ 0x17120220 1 >,
				<DCC_READ 0x17120228 1 >,
				<DCC_READ 0x17120240 1 >,
				<DCC_READ 0x17120248 1 >,
				<DCC_READ 0x17120250 1 >,
				<DCC_READ 0x17120258 1 >,
				<DCC_READ 0x17120260 1 >,
				<DCC_READ 0x17120268 1 >,
				<DCC_READ 0x17120280 1 >,
				<DCC_READ 0x17120288 1 >,
				<DCC_READ 0x17120290 1 >,
				<DCC_READ 0x17120298 1 >,
				<DCC_READ 0x171202a0 1 >,
				<DCC_READ 0x171202a8 1 >,
				<DCC_READ 0x171202c0 1 >,
				<DCC_READ 0x171202c8 1 >,
				<DCC_READ 0x171202d0 1 >,
				<DCC_READ 0x171202d8 1 >,
				<DCC_READ 0x171202e0 1 >,
				<DCC_READ 0x171202e8 1 >,
				<DCC_READ 0x17120300 1 >,
				<DCC_READ 0x17120308 1 >,
				<DCC_READ 0x17120310 1 >,
				<DCC_READ 0x17120318 1 >,
				<DCC_READ 0x17120320 1 >,
				<DCC_READ 0x17120328 1 >,
				<DCC_READ 0x17120340 1 >,
				<DCC_READ 0x17120348 1 >,
				<DCC_READ 0x17120350 1 >,
				<DCC_READ 0x17120358 1 >,
				<DCC_READ 0x17120360 1 >,
				<DCC_READ 0x17120368 1 >,
				<DCC_READ 0x17120380 1 >,
				<DCC_READ 0x17120388 1 >,
				<DCC_READ 0x17120390 1 >,
				<DCC_READ 0x17120398 1 >,
				<DCC_READ 0x171203a0 1 >,
				<DCC_READ 0x171203a8 1 >,
				<DCC_READ 0x171203c0 1 >,
				<DCC_READ 0x171203c8 1 >,
				<DCC_READ 0x171203d0 1 >,
				<DCC_READ 0x171203d8 1 >,
				<DCC_READ 0x171203e0 1 >,
				<DCC_READ 0x171203e8 1 >,
				<DCC_READ 0x17120400 1 >,
				<DCC_READ 0x17120408 1 >,
				<DCC_READ 0x17120410 1 >,
				<DCC_READ 0x17120418 1 >,
				<DCC_READ 0x17120420 1 >,
				<DCC_READ 0x17120428 1 >,
				<DCC_READ 0x17120440 1 >,
				<DCC_READ 0x17120448 1 >,
				<DCC_READ 0x17120450 1 >,
				<DCC_READ 0x17120458 1 >,
				<DCC_READ 0x17120460 1 >,
				<DCC_READ 0x17120468 1 >,
				<DCC_READ 0x17120480 1 >,
				<DCC_READ 0x17120488 1 >,
				<DCC_READ 0x17120490 1 >,
				<DCC_READ 0x17120498 1 >,
				<DCC_READ 0x171204a0 1 >,
				<DCC_READ 0x171204a8 1 >,
				<DCC_READ 0x171204c0 1 >,
				<DCC_READ 0x171204c8 1 >,
				<DCC_READ 0x171204d0 1 >,
				<DCC_READ 0x171204d8 1 >,
				<DCC_READ 0x171204e0 1 >,
				<DCC_READ 0x171204e8 1 >,
				<DCC_READ 0x17120500 1 >,
				<DCC_READ 0x17120508 1 >,
				<DCC_READ 0x17120510 1 >,
				<DCC_READ 0x17120518 1 >,
				<DCC_READ 0x17120520 1 >,
				<DCC_READ 0x17120528 1 >,
				<DCC_READ 0x17120540 1 >,
				<DCC_READ 0x17120548 1 >,
				<DCC_READ 0x17120550 1 >,
				<DCC_READ 0x17120558 1 >,
				<DCC_READ 0x17120560 1 >,
				<DCC_READ 0x17120568 1 >,
				<DCC_READ 0x17120580 1 >,
				<DCC_READ 0x17120588 1 >,
				<DCC_READ 0x17120590 1 >,
				<DCC_READ 0x17120598 1 >,
				<DCC_READ 0x171205a0 1 >,
				<DCC_READ 0x171205a8 1 >,
				<DCC_READ 0x171205c0 1 >,
				<DCC_READ 0x171205c8 1 >,
				<DCC_READ 0x171205d0 1 >,
				<DCC_READ 0x171205d8 1 >,
				<DCC_READ 0x171205e0 1 >,
				<DCC_READ 0x171205e8 1 >,
				<DCC_READ 0x17120600 1 >,
				<DCC_READ 0x17120608 1 >,
				<DCC_READ 0x17120610 1 >,
				<DCC_READ 0x17120618 1 >,
				<DCC_READ 0x17120620 1 >,
				<DCC_READ 0x17120628 1 >,
				<DCC_READ 0x17120640 1 >,
				<DCC_READ 0x17120648 1 >,
				<DCC_READ 0x17120650 1 >,
				<DCC_READ 0x17120658 1 >,
				<DCC_READ 0x17120660 1 >,
				<DCC_READ 0x17120668 1 >,
				<DCC_READ 0x17120680 1 >,
				<DCC_READ 0x17120688 1 >,
				<DCC_READ 0x17120690 1 >,
				<DCC_READ 0x17120698 1 >,
				<DCC_READ 0x171206a0 1 >,
				<DCC_READ 0x171206a8 1 >,
				<DCC_READ 0x171206c0 1 >,
				<DCC_READ 0x171206c8 1 >,
				<DCC_READ 0x171206d0 1 >,
				<DCC_READ 0x171206d8 1 >,
				<DCC_READ 0x171206e0 1 >,
				<DCC_READ 0x171206e8 1 >,
				<DCC_READ 0x1712e000 1 >,
				<DCC_READ 0x17603c 1 0>,
				<DCC_READ 0x16c000 1 0>,
				<DCC_READ 0x16c01c 1 0>,
				<DCC_READ 0x10c0000 4 >,
				<DCC_READ 0x10c1000 2 >,
				<DCC_READ 0x10c1010 7 >,
				<DCC_READ 0x10c1100 3 >,
				<DCC_READ 0x10c1110 5 >,
				<DCC_READ 0x10c1130 2 >,
				<DCC_READ 0x10c113c 2 >,
				<DCC_READ 0x10c1148 3 >,
				<DCC_READ 0x10c2000 1 >,
				<DCC_READ 0x10cf004 1 >,
				<DCC_READ 0x110018 7 0>,
				<DCC_READ 0x11c018 7 0>,
				<DCC_READ 0x178040 1 >,
				<DCC_READ 0x199014 7 0>,
				<DCC_READ 0x19d014 7 0>,
				<DCC_READ 0x183004 5 0>,
				<DCC_READ 0x18301c 3 0>,
				<DCC_READ 0x193480 1 >,
				<DCC_READ 0x110040 7 0>,
				<DCC_READ 0x110064 1 >,
				<DCC_READ 0x110070 2 0>,
				<DCC_READ 0x111004 2 0>,
				<DCC_READ 0x16b018 3 0>,
				<DCC_READ 0x16b02c 1 >,
				<DCC_READ 0x16b038 2 0>,
				<DCC_READ 0x16b048 1 >,
				<DCC_READ 0x16b054 1 >,
				<DCC_READ 0x16b098 1 >,
				<DCC_READ 0x1c00000 1 >,
				<DCC_READ 0x1c00024 2 0>,
				<DCC_READ 0x1c001b0 1 >,
				<DCC_READ 0x1c001b0   1 >,
				<DCC_READ 0x1c00224 1 >,
				<DCC_READ 0x1c00230	 1 >,
				<DCC_READ 0x1c002b0 1 >,
				<DCC_READ 0x1c003c0 1 >,
				<DCC_READ 0x1c004d0 2 0>,
				<DCC_READ 0x1c00500 1 >,
				<DCC_READ 0x1c00630 1 >,
				<DCC_READ 0x1c061c8	 8 0>,
				<DCC_READ 0x1c061f8 1 >,
				<DCC_READ 0x1c06214	 1 >,
				<DCC_READ 0x1c06214	 11 0>,
				<DCC_READ 0x1c06600	 2 0>,
				<DCC_READ 0x1c06804 1 >,
				<DCC_READ 0x1c06a00	 4 0>,
				<DCC_READ 0x1c06a18 1 >,
				<DCC_READ 0x1c06c20  1 >,
				<DCC_READ 0x1c07204 1 >,
				<DCC_READ 0x1ff1100 1 >,
				<DCC_READ 0x60000080	 1 >,
				<DCC_READ 0x60000104	 1 >,
				<DCC_READ 0x60000110 1 >,
				<DCC_READ 0x60000204	 1 >,
				<DCC_READ 0x60000730 4 0>,
				<DCC_READ 0x0c222004 1 0>,
				<DCC_READ 0x0c228014 1 0>,
				<DCC_READ 0x0c2280e0 1 0>,
				<DCC_READ 0x0c2280ec 1 0>,
				<DCC_READ 0x0c2280a0 16 0>,
				<DCC_READ 0x0c2280e8 1 0>,
				<DCC_READ 0x0c22813c 1 0>,
				<DCC_READ 0x0c223004 1 0>,
				<DCC_READ 0x0c229014 1 0>,
				<DCC_READ 0x0c2290e0 1 0>,
				<DCC_READ 0x0c2290ec 1 0>,
				<DCC_READ 0x0c2290a0 16 0>,
				<DCC_READ 0x0c2290e8 1 0>,
				<DCC_READ 0x0c22913c 1 0>,
				<DCC_READ 0xec80010 1 0>,
				<DCC_READ 0xec81000 1 0>,
				<DCC_READ 0xec81010 161 0>,
				<DCC_READ 0xec81050 16 0>,
				<DCC_READ 0xec81090 16 0>,
				<DCC_READ 0xec810d0 16 0>,
				<DCC_READ 0xec81110 16 0>,
				<DCC_READ 0xec81550 1 0>,
				<DCC_READ 0x17b70220 6 0>,
				<DCC_READ 0x17b702a0 6 0>,
				<DCC_READ 0x17b70320 1 0>,
				<DCC_READ 0x17b704a0 16 0>,
				<DCC_READ 0x17b70520 1 0>,
				<DCC_READ 0x17b70524 1 0>,
				<DCC_READ 0x17b70588 1 0>,
				<DCC_READ 0x17b70630  2>,
				<DCC_READ 0x17b70638  2>,
				<DCC_READ 0x17b70640   2>,
				<DCC_READ 0x17b71010  24>,
				<DCC_READ 0x17b71310   16>,
				<DCC_READ 0x17b71390   16>,
				<DCC_READ 0x17b72090   8>,
				<DCC_READ 0x17b784a0 12 0>,
				<DCC_READ 0x17b78520 1 0>,
				<DCC_READ 0x17b78588 1 0>,
				<DCC_READ 0x17b78630    2 1 0>,
				<DCC_READ 0x17b78638  2>,
				<DCC_READ 0x17b78640   2>,
				<DCC_READ 0x17b79010  8>,
				<DCC_READ 0x17b79310   6>,
				<DCC_READ 0x17b79390  6>,
				<DCC_READ 0x17b7a090   4>,
				<DCC_READ 0x32310220 4 0>,
				<DCC_READ 0x323102a0 4 0>,
				<DCC_READ 0x323104a0 6 0>,
				<DCC_READ 0x32310520 1 0>,
				<DCC_READ 0x32310588 1 0>,
				<DCC_READ 0x32310630  2>,
				<DCC_READ 0x32310638  2>,
				<DCC_READ 0x32310640  2>,
				<DCC_READ 0x32311010  8>,
				<DCC_READ 0x32311310   6>,
				<DCC_READ 0x32311390   6>,
				<DCC_READ 0x32312090   3>,
				<DCC_READ 0x240e0000 3 0>,
				<DCC_READ 0x240e0010 1 >,
				<DCC_READ 0x240e0018 1 >,
				<DCC_READ 0x240e0020 8 0>,
				<DCC_READ 0x240e0240 1 >,
				<DCC_READ 0x240e0248 1 >,
				<DCC_READ 0x247f0000 3 0>,
				<DCC_READ 0x247f0010 1 >,
				<DCC_READ 0x247f0018 1 >,
				<DCC_READ 0x247f0020 8 0>,
				<DCC_READ 0x247f0240 1 >,
				<DCC_READ 0x247f0248 1 >,
				<DCC_READ 0x247f2018 1 0>,
				<DCC_READ 0x247f2008 1 0>,
				<DCC_LOOP 0x3  0 0>,
				<DCC_READ 0x247f2010 2 0>,
				<DCC_LOOP 0x1 0 0>,
				<DCC_READ 0x3c40008 1 >,
				<DCC_READ 0x3c40010 1 >,
				<DCC_READ 0x3c40018 1 >,
				<DCC_READ 0x3c40020 8 0>,
				<DCC_READ 0x3c44010 1 >,
				<DCC_READ 0x3c45010 1 >,
				<DCC_READ 0x3c46010 1 >,
				<DCC_READ 0x3c4b040 1 >,
				<DCC_READ 0x3c4b048 1 >,
				<DCC_READ 0x3c50008 1 >,
				<DCC_READ 0x3c50010 1 >,
				<DCC_READ 0x3c50018 1 >,
				<DCC_READ 0x3c50020 8 0>,
				<DCC_READ 0x3c54010 1 >,
				<DCC_READ 0x3c56040 1 >,
				<DCC_READ 0x3c56048 1 >,
				<DCC_READ 0x3c41008 1 0>,
				<DCC_READ 0x3c41018 1 0>,
				<DCC_LOOP 0x5  0 0>,
				<DCC_READ 0x3c41010 2 0>,
				<DCC_LOOP 0x1 0 0>,
				<DCC_READ 0x3c51008 1 0>,
				<DCC_READ 0x3c51018 1 0>,
				<DCC_LOOP 0x2  0 0>,
				<DCC_READ 0x3c51010 2 0>,
				<DCC_LOOP 0x1 0 0>,
				<DCC_READ 0x320c0008 1 >,
				<DCC_READ 0x320c0010 1 >,
				<DCC_READ 0x320c0018 1 >,
				<DCC_READ 0x320c0020 8 0>,
				<DCC_READ 0x320c0240 1 >,
				<DCC_READ 0x320c0248 1 >,
				<DCC_READ 0x320cc010 1 >,
				<DCC_READ 0x320cd010 1 >,
				<DCC_READ 0x320ce010 1 >,
				<DCC_READ 0x320c1008 1 >,
				<DCC_READ 0x320c1018 1 >,
				<DCC_LOOP 0x5  0 0>,
				<DCC_READ 0x320c1010 2 0>,
				<DCC_LOOP 0x1 0 0>,
				<DCC_READ 0x17a80000 17 0>,
				<DCC_READ 0x17a84000 17 0>,
				<DCC_READ 0x17a90000 25 0>,
				<DCC_READ 0x17a90080 16 0>,
				<DCC_READ 0x17a900cc 5 0>,
				<DCC_READ 0x17a900e4 2 0>,
				<DCC_READ 0x17a900f0 1 >,
				<DCC_READ 0x17a900f8 1 >,
				<DCC_READ 0x17a90118 1 >,
				<DCC_READ 0x17a94000 25 0>,
				<DCC_READ 0x17a94080 16 0>,
				<DCC_READ 0x17a940cc 5 0>,
				<DCC_READ 0x17a940e4 2 0>,
				<DCC_READ 0x17a940f0 1 >,
				<DCC_READ 0x17a940f8 1 >,
				<DCC_READ 0x17a94118 1 >,
				<DCC_READ 0x17aa0000 44 0>,
				<DCC_READ 0x17aa00bc 1 >,
				<DCC_READ 0x17aa00fc 20 0>,
				<DCC_READ 0x17aa0200 2 0>,
				<DCC_READ 0x17aa0300 1 >,
				<DCC_READ 0x17aa0400 1 >,
				<DCC_READ 0x17aa0500 1 >,
				<DCC_READ 0x17aa0600 1 >,
				<DCC_READ 0x17aa0700 5 0>,
				<DCC_READ 0x17d90000 4 0>,
				<DCC_READ 0x17d90014 26 0>,
				<DCC_READ 0x17d90080 5 0>,
				<DCC_READ 0x17d900b0 1 >,
				<DCC_READ 0x17d900b8 2 0>,
				<DCC_READ 0x17d900d0 9 0>,
				<DCC_READ 0x17d90100 1 >,
				<DCC_READ 0x17d90200 1 >,
				<DCC_READ 0x17d90300 5 0>,
				<DCC_READ 0x17d90320 1 >,
				<DCC_READ 0x17d9034c 2 0>,
				<DCC_READ 0x17d90360 5 0>,
				<DCC_READ 0x17d903b0 6 0>,
				<DCC_READ 0x17d903e0 2 0>,
				<DCC_READ 0x17d90404 3 0>,
				<DCC_READ 0x17d90420 1 >,
				<DCC_READ 0x17d90430 1 >,
				<DCC_READ 0x17d90450 1 >,
				<DCC_READ 0x17d90470 6 0>,
				<DCC_READ 0x17d91000 4 0>,
				<DCC_READ 0x17d91014 26 0>,
				<DCC_READ 0x17d91080 5 0>,
				<DCC_READ 0x17d910b0 1 >,
				<DCC_READ 0x17d910b8 2 0>,
				<DCC_READ 0x17d910d0 9 0>,
				<DCC_READ 0x17d91100 1 >,
				<DCC_READ 0x17d91200 1 >,
				<DCC_READ 0x17d91300 5 0>,
				<DCC_READ 0x17d91320 1 >,
				<DCC_READ 0x17d9134c 2 0>,
				<DCC_READ 0x17d91360 5 0>,
				<DCC_READ 0x17d913b0 6 0>,
				<DCC_READ 0x17d913e0 2 0>,
				<DCC_READ 0x17d91404 3 0>,
				<DCC_READ 0x17d91420 1 >,
				<DCC_READ 0x17d91430 1 >,
				<DCC_READ 0x17d91450 1 >,
				<DCC_READ 0x17d91470 4 0>,
				<DCC_READ 0x17d91480 1 >,
				<DCC_READ 0x11c018 7 0>,
				<DCC_READ 0x178040 1 >,
				<DCC_READ 0x190890 1 >,
				<DCC_READ 0x199014 7 0>,
				<DCC_READ 0x19d014 7 0>,
				<DCC_READ 0x1fd5000 10 0>,
				<DCC_READ 0x1fd502c 1 >,
				<DCC_READ 0x1fd5030 4 0>,
				<DCC_READ 0x88e7000 51 0>,
				<DCC_READ 0x17421000 2 0>;
		};
	};

	mem_dump {
		compatible = "qcom,mem-dump";
		memory-region = <&dump_mem>;

		c0_context {
			qcom,dump-size = <0x800>;
			qcom,dump-id = <0x0>;
		};

		c100_context {
			qcom,dump-size = <0x800>;
			qcom,dump-id = <0x1>;
		};

		c200_context {
			qcom,dump-size = <0x800>;
			qcom,dump-id = <0x2>;
		};

		c300_context {
			qcom,dump-size = <0x800>;
			qcom,dump-id = <0x3>;
		};

		c400_context {
			qcom,dump-size = <0x800>;
			qcom,dump-id = <0x4>;
		};

		c500_context {
			qcom,dump-size = <0x800>;
			qcom,dump-id = <0x5>;
		};

		c600_context {
			qcom,dump-size = <0x800>;
			qcom,dump-id = <0x6>;
		};

		c700_context {
			qcom,dump-size = <0x800>;
			qcom,dump-id = <0x7>;
		};

		l1_icache0 {
			qcom,dump-size = <0x22100>;
			qcom,dump-id = <0x60>;
		};

		l1_icache100 {
			qcom,dump-size = <0x22100>;
			qcom,dump-id = <0x61>;
		};

		l1_icache200 {
			qcom,dump-size = <0x22100>;
			qcom,dump-id = <0x62>;
		};

		l1_icache300 {
			qcom,dump-size = <0x22100>;
			qcom,dump-id = <0x63>;
		};

		l1_icache400 {
			qcom,dump-size = <0x22100>;
			qcom,dump-id = <0x64>;
		};

		l1_icache500 {
			qcom,dump-size = <0x22100>;
			qcom,dump-id = <0x65>;
		};

		l1_icache600 {
			qcom,dump-size = <0x22100>;
			qcom,dump-id = <0x66>;
		};

		l1_icache700 {
			qcom,dump-size = <0x22100>;
			qcom,dump-id = <0x67>;
		};

		l1_dcache0 {
			qcom,dump-size = <0x12100>;
			qcom,dump-id = <0x80>;
		};

		l1_dcache100 {
			qcom,dump-size = <0x12100>;
			qcom,dump-id = <0x81>;
		};

		l1_dcache200 {
			qcom,dump-size = <0x1a100>;
			qcom,dump-id = <0x82>;
		};

		l1_dcache300 {
			qcom,dump-size = <0x1a100>;
			qcom,dump-id = <0x83>;
		};

		l1_dcache400 {
			qcom,dump-size = <0x1a100>;
			qcom,dump-id = <0x84>;
		};

		l1_dcache500 {
			qcom,dump-size = <0x1a100>;
			qcom,dump-id = <0x85>;
		};

		l1_dcache600 {
			qcom,dump-size = <0x1a100>;
			qcom,dump-id = <0x86>;
		};

		l1_dcache700 {
			qcom,dump-size = <0x1a100>;
			qcom,dump-id = <0x87>;
		};

		l1_itlb700 {
			qcom,dump-size = <0x600>;
			qcom,dump-id = <0x27>;
		};

		l1_dtlb700 {
			qcom,dump-size = <0xa00>;
			qcom,dump-id = <0x47>;
		};

		l2_cache0 {
			qcom,dump-size = <0x90100>;
			qcom,dump-id = <0xc0>;
		};

		l2_cache100 {
			qcom,dump-size = <0x90100>;
			qcom,dump-id = <0xc1>;
		};

		l2_cache200 {
			qcom,dump-size = <0xd0100>;
			qcom,dump-id = <0xc2>;
		};

		l2_cache300 {
			qcom,dump-size = <0xd0100>;
			qcom,dump-id = <0xc3>;
		};

		l2_cache400 {
			qcom,dump-size = <0xd0100>;
			qcom,dump-id = <0xc4>;
		};

		l2_cache500 {
			qcom,dump-size = <0xd0100>;
			qcom,dump-id = <0xc5>;
		};

		l2_cache600 {
			qcom,dump-size = <0xd0100>;
			qcom,dump-id = <0xc6>;
		};

		l2_cache700 {
			qcom,dump-size = <0x340100>;
			qcom,dump-id = <0xc7>;
		};

		l2_tlb0 {
			qcom,dump-size = <0xf700>;
			qcom,dump-id = <0x120>;
		};

		l2_tlb100 {
			qcom,dump-size = <0xf700>;
			qcom,dump-id = <0x121>;
		};

		l2_tlb700 {
			qcom,dump-size = <0xa900>;
			qcom,dump-id = <0x127>;
		};

		l1dcdirty0 {
			qcom,dump-size = <0x2100>;
			qcom,dump-id = <0x170>;
		};

		l1dcdirty100 {
			qcom,dump-size = <0x2100>;
			qcom,dump-id = <0x171>;
		};

		l1dcmte0 {
			qcom,dump-size = <0x2100>;
			qcom,dump-id = <0x180>;
		};

		l1dcmte100 {
			qcom,dump-size = <0x2100>;
			qcom,dump-id = <0x181>;
		};

		l2dcmte0 {
			qcom,dump-size = <0x10100>;
			qcom,dump-id = <0x190>;
		};

		l2dcmte100 {
			qcom,dump-size = <0x10100>;
			qcom,dump-id = <0x191>;
		};

		l0mopca700 {
			qcom,dump-size = <0x4100>;
			qcom,dump-id = <0x1a7>;
		};

		l2victim700 {
			qcom,dump-size = <0x2100>;
			qcom,dump-id = <0x1e7>;
		};

		l2tldtcsp200 {
			qcom,dump-size = <0x7900>;
			qcom,dump-id = <0x202>;
		};

		l2tldtcsp300 {
			qcom,dump-size = <0x7900>;
			qcom,dump-id = <0x203>;
		};

		l2tldtcsp400 {
			qcom,dump-size = <0x7900>;
			qcom,dump-id = <0x204>;
		};

		l2tldtcsp500 {
			qcom,dump-size = <0x7900>;
			qcom,dump-id = <0x205>;
		};

		l2tldtcsp600 {
			qcom,dump-size = <0x7900>;
			qcom,dump-id = <0x206>;
		};

		l2tldtcmp200 {
			qcom,dump-size = <0x1300>;
			qcom,dump-id = <0x212>;
		};

		l2tldtcmp300 {
			qcom,dump-size = <0x1300>;
			qcom,dump-id = <0x213>;
		};

		l2tldtcmp400 {
			qcom,dump-size = <0x1300>;
			qcom,dump-id = <0x214>;
		};

		l2tldtcmp500 {
			qcom,dump-size = <0x1300>;
			qcom,dump-id = <0x215>;
		};

		l2tldtcmp600 {
			qcom,dump-size = <0x1300>;
			qcom,dump-id = <0x216>;
		};

		cpuss_reg {
			qcom,dump-size = <0x36000>;
			qcom,dump-id = <0xef>;
		};

		rpmh {
			qcom,dump-size = <0x400000>;
			qcom,dump-id = <0xec>;
		};

		rpm_sw {
			qcom,dump-size = <0x28000>;
			qcom,dump-id = <0xea>;
		};

		pmic {
			qcom,dump-size = <0x200000>;
			qcom,dump-id = <0xe4>;
		};

		fcm {
			qcom,dump-size = <0x8400>;
			qcom,dump-id = <0xee>;
		};

		etf_swao {
			qcom,dump-size = <0x10000>;
			qcom,dump-id = <0xf1>;
		};

		etr_reg {
			qcom,dump-size = <0x1000>;
			qcom,dump-id = <0x100>;
		};

		etfswao_reg {
			qcom,dump-size = <0x1000>;
			qcom,dump-id = <0x102>;
		};

		etr1_reg {
			qcom,dump-size = <0x1000>;
			qcom,dump-id = <0x105>;
		};

		misc_data {
			qcom,dump-size = <0x1000>;
			qcom,dump-id = <0xe8>;
		};

		etf_slpi {
			qcom,dump-size = <0x4000>;
			qcom,dump-id = <0xf3>;
		};

		etfslpi_reg {
			qcom,dump-size = <0x1000>;
			qcom,dump-id = <0x103>;
		};

		etf_lpass {
			qcom,dump-size = <0x4000>;
			qcom,dump-id = <0xf4>;
		};

		etflpass_reg {
			qcom,dump-size = <0x1000>;
			qcom,dump-id = <0x104>;
		};

		osm_reg {
			qcom,dump-size = <0x400>;
			qcom,dump-id = <0x163>;
		};

		pcu_reg {
			qcom,dump-size = <0x400>;
			qcom,dump-id = <0x164>;
		};

		fsm_data {
			qcom,dump-size = <0x400>;
			qcom,dump-id = <0x165>;
		};

		spr_cpu0 {
			qcom,dump-size = <0x2000>;
			qcom,dump-id = <0x1f0>;
		};

		spr_cpu1 {
			qcom,dump-size = <0x2000>;
			qcom,dump-id = <0x1f1>;
		};

		spr_cpu2 {
			qcom,dump-size = <0x2000>;
			qcom,dump-id = <0x1f2>;
		};

		spr_cpu3 {
			qcom,dump-size = <0x2000>;
			qcom,dump-id = <0x1f3>;
		};

		spr_cpu4 {
			qcom,dump-size = <0x2000>;
			qcom,dump-id = <0x1f4>;
		};

		spr_cpu5 {
			qcom,dump-size = <0x2000>;
			qcom,dump-id = <0x1f5>;
		};

		spr_cpu6 {
			qcom,dump-size = <0x2000>;
			qcom,dump-id = <0x1f6>;
		};

		spr_cpu7 {
			qcom,dump-size = <0x2000>;
			qcom,dump-id = <0x1f7>;
		};

		scandump_smmu {
			qcom,dump-size = <0x40000>;
			qcom,dump-id = <0x220>;
		};

		scandump_gpu {
			qcom,dump-size = <0x300000>;
			qcom,dump-id = <0x221>;
		};
	};
};
